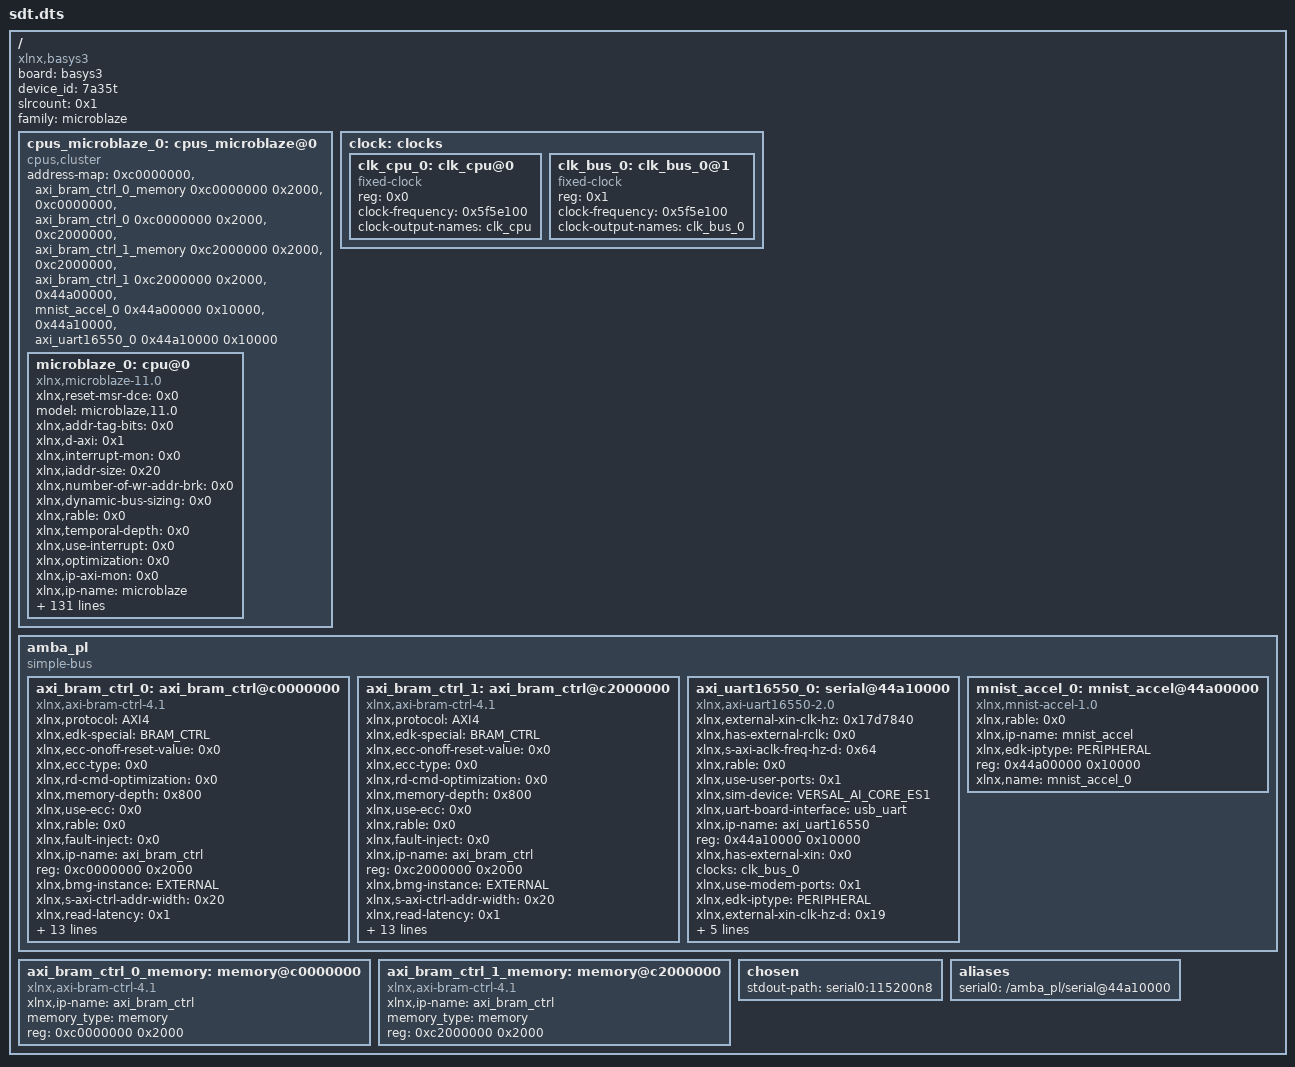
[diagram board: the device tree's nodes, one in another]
/dts-v1/;

/ {
        board = "basys3";
        compatible = "xlnx,basys3";
        device_id = "7a35t";
        #address-cells = <0x1>;
        #size-cells = <0x1>;
        slrcount = <0x1>;
        family = "microblaze";

        cpus_microblaze_0: cpus_microblaze@0 {
                #cpu-mask-cells = <0x1>;
                compatible = "cpus,cluster";
                #address-cells = <0x1>;
                #size-cells = <0x0>;
                address-map = <0xc0000000 &axi_bram_ctrl_0_memory 0xc0000000 0x2000>,
                 <0xc0000000 &axi_bram_ctrl_0 0xc0000000 0x2000>,
                 <0xc2000000 &axi_bram_ctrl_1_memory 0xc2000000 0x2000>,
                 <0xc2000000 &axi_bram_ctrl_1 0xc2000000 0x2000>,
                 <0x44a00000 &mnist_accel_0 0x44a00000 0x10000>,
                 <0x44a10000 &axi_uart16550_0 0x44a10000 0x10000>;
                #ranges-address-cells = <0x1>;
                #ranges-size-cells = <0x1>;
                phandle = <0x9>;

                microblaze_0: cpu@0 {
                        xlnx,reset-msr-dce = <0x0>;
                        model = "microblaze,11.0";
                        xlnx,addr-tag-bits = <0x0>;
                        xlnx,d-axi = <0x1>;
                        xlnx,interrupt-mon = <0x0>;
                        xlnx,iaddr-size = <0x20>;
                        xlnx,number-of-wr-addr-brk = <0x0>;
                        xlnx,dynamic-bus-sizing = <0x0>;
                        xlnx,rable = <0x0>;
                        xlnx,temporal-depth = <0x0>;
                        xlnx,use-interrupt = <0x0>;
                        xlnx,optimization = <0x0>;
                        xlnx,ip-axi-mon = <0x0>;
                        xlnx,ip-name = "microblaze";
                        d-cache-highaddr = <0x3fffffff>;
                        xlnx,dcache-force-tag-lutram = <0x0>;
                        xlnx,pc-width = <0x20>;
                        xlnx,interrupt-is-edge = <0x0>;
                        reg = <0x0>;
                        xlnx,async-interrupt = <0x1>;
                        xlnx,use-mmu = <0x0>;
                        xlnx,reset-msr-ee = <0x0>;
                        xlnx,icache-victims = <0x0>;
                        xlnx,use-reorder-instr = <0x1>;
                        xlnx,d-lmb-mon = <0x0>;
                        xlnx,d-lmb-protocol = <0x0>;
                        xlnx,ill-opcode-exception = <0x0>;
                        xlnx,dcache-always-used = <0x1>;
                        xlnx,use-div = <0x0>;
                        xlnx,dc-axi-mon = <0x0>;
                        xlnx,debug-trace-async-reset = <0x0>;
                        xlnx,trace = <0x0>;
                        xlnx,part = "xc7a35tcpg236-1";
                        i-cache-baseaddr = <0x0>;
                        xlnx,use-config-reset = <0x0>;
                        xlnx,pvr = <0x0>;
                        xlnx,i-lmb-mon = <0x0>;
                        xlnx,dcache-byte-size = <0x2000>;
                        xlnx,fault-tolerant = <0x1>;
                        xlnx,family = "artix7";
                        compatible = "xlnx,microblaze-11.0", "xlnx,microblaze";
                        xlnx,data-size = <0x20>;
                        xlnx,mmu-zones = <0x10>;
                        xlnx,debug-trace-size = <0x2000>;
                        xlnx,mmu-privileged-instr = <0x0>;
                        xlnx,enable-discrete-ports = <0x0>;
                        d-cache-line-size = <0x10>;
                        xlnx,d-lmb = <0x0>;
                        xlnx,sco = <0x0>;
                        xlnx,reset-msr-eip = <0x0>;
                        xlnx,debug-interface = <0x0>;
                        clock-frequency = <0x5f5e100>;
                        xlnx,use-ext-brk = <0x0>;
                        xlnx,daddr-size = <0x20>;
                        xlnx,debug-enabled = <0x1>;
                        xlnx,reset-msr-ice = <0x0>;
                        xlnx,num-sync-ff-dbg-trace-clk = <0x2>;
                        xlnx,i-lmb-protocol = <0x0>;
                        xlnx,endianness = <0x1>;
                        xlnx,fsl-exception = <0x0>;
                        i-cache-line-size = <0x10>;
                        xlnx,use-extended-fsl-instr = <0x0>;
                        xlnx,reset-msr = <0x0>;
                        xlnx,dp-axi-mon = <0x0>;
                        device_type = "cpu";
                        xlnx,branch-target-cache-size = <0x0>;
                        xlnx,dcache-use-writeback = <0x0>;
                        xlnx,div-zero-exception = <0x0>;
                        xlnx,mmu-tlb-access = <0x3>;
                        bus-handle = <0x7>;
                        xlnx,cache-byte-size = <0x2000>;
                        xlnx,pvr-user2 = <0x0>;
                        xlnx,opcode-0x0-illegal = <0x0>;
                        xlnx,icache-line-len = <0x4>;
                        xlnx,ecc-use-ce-exception = <0x0>;
                        xlnx,base-vectors = <0xc0000000>;
                        xlnx,edk-special = "microblaze";
                        xlnx,use-dcache = <0x0>;
                        xlnx,use-barrel = <0x0>;
                        xlnx,reset-msr-bip = <0x0>;
                        xlnx,allow-dcache-wr = <0x1>;
                        xlnx,addr-size = <0x20>;
                        xlnx,debug-external-trace = <0x0>;
                        xlnx,piaddr-size = <0x20>;
                        i-cache-highaddr = <0x3fffffff>;
                        xlnx,num-sync-ff-clk-debug = <0x2>;
                        xlnx,debug-event-counters = <0x5>;
                        xlnx,fpu-exception = <0x0>;
                        xlnx,allow-icache-wr = <0x1>;
                        xlnx,g-use-exceptions = <0x0>;
                        xlnx,i-axi = <0x1>;
                        xlnx,g-template-list = <0x0>;
                        xlnx,icache-streams = <0x0>;
                        xlnx,dcache-line-len = <0x4>;
                        xlnx,num-sync-ff-clk = <0x2>;
                        xlnx,edk-iptype = "PROCESSOR";
                        xlnx,use-stack-protection = <0x0>;
                        xlnx,use-hw-mul = <0x0>;
                        xlnx,num-sync-ff-dbg-clk = <0x1>;
                        xlnx,interconnect = <0x2>;
                        xlnx,debug-latency-counters = <0x1>;
                        i-cache-size = <0x2000>;
                        xlnx,exceptions-in-delay-slots = <0x1>;
                        xlnx,use-fpu = <0x0>;
                        xlnx,reset-msr-ie = <0x0>;
                        xlnx,edge-is-positive = <0x1>;
                        xlnx,use-pcmp-instr = <0x0>;
                        xlnx,use-icache = <0x0>;
                        d-cache-size = <0x2000>;
                        xlnx,memory-ip-list = "axi_bram_ctrl_0_memory", "axi_bram_ctrl_0_memory", "axi_bram_ctrl_1_memory", "axi_bram_ctrl_1_memory";
                        xlnx,async-wakeup = <0x3>;
                        xlnx,use-non-secure = <0x0>;
                        xlnx,dcache-addr-tag = <0x0>;
                        xlnx,number-of-rd-addr-brk = <0x0>;
                        d-cache-baseaddr = <0x0>;
                        xlnx,area-optimized = <0x0>;
                        xlnx,avoid-primitives = <0x0>;
                        xlnx,lockstep-slave = <0x0>;
                        xlnx,use-ext-nm-brk = <0x0>;
                        xlnx,instr-size = <0x20>;
                        xlnx,icache-always-used = <0x1>;
                        xlnx,i-lmb = <0x0>;
                        xlnx,mmu-dtlb-size = <0x4>;
                        xlnx,lockstep-select = <0x0>;
                        xlnx,lmb-data-size = <0x20>;
                        xlnx,ic-axi-mon = <0x0>;
                        xlnx,enable-conversion = <0x0>;
                        xlnx,num-sync-ff-clk-irq = <0x1>;
                        xlnx,fsl-links = <0x0>;
                        timebase-frequency = <0x5f5e100>;
                        xlnx,icache-force-tag-lutram = <0x0>;
                        xlnx,dcache-data-width = <0x0>;
                        xlnx,dcache-victims = <0x0>;
                        xlnx,use-branch-target-cache = <0x0>;
                        xlnx,debug-profile-size = <0x0>;
                        xlnx,unaligned-exceptions = <0x0>;
                        xlnx,lockstep-master = <0x0>;
                        xlnx,freq = <0x5f5e100>;
                        xlnx,number-of-pc-brk = <0x1>;
                        xlnx,mmu-itlb-size = <0x2>;
                        xlnx,imprecise-exceptions = <0x0>;
                        xlnx,use-msr-instr = <0x0>;
                        xlnx,icache-data-width = <0x0>;
                        xlnx,debug-counter-width = <0x20>;
                        phandle = <0xa>;
                };
        };

        clock: clocks {
                #address-cells = <0x1>;
                #size-cells = <0x0>;
                phandle = <0xb>;

                clk_cpu_0: clk_cpu@0 {
                        compatible = "fixed-clock";
                        reg = <0x0>;
                        clock-frequency = <0x5f5e100>;
                        clock-output-names = "clk_cpu";
                        #clock-cells = <0x0>;
                        phandle = <0xc>;
                };

                clk_bus_0: clk_bus_0@1 {
                        compatible = "fixed-clock";
                        reg = <0x1>;
                        clock-frequency = <0x5f5e100>;
                        clock-output-names = "clk_bus_0";
                        #clock-cells = <0x0>;
                        phandle = <0x8>;
                };
        };

        amba_pl: amba_pl {
                ranges;
                compatible = "simple-bus";
                #address-cells = <0x1>;
                #size-cells = <0x1>;
                phandle = <0x7>;

                axi_bram_ctrl_0: axi_bram_ctrl@c0000000 {
                        xlnx,protocol = "AXI4";
                        xlnx,edk-special = "BRAM_CTRL";
                        compatible = "xlnx,axi-bram-ctrl-4.1";
                        xlnx,ecc-onoff-reset-value = <0x0>;
                        xlnx,ecc-type = <0x0>;
                        xlnx,rd-cmd-optimization = <0x0>;
                        xlnx,memory-depth = <0x800>;
                        xlnx,use-ecc = <0x0>;
                        xlnx,rable = <0x0>;
                        xlnx,fault-inject = <0x0>;
                        xlnx,ip-name = "axi_bram_ctrl";
                        reg = <0xc0000000 0x2000>;
                        xlnx,bmg-instance = "EXTERNAL";
                        xlnx,s-axi-ctrl-addr-width = <0x20>;
                        xlnx,read-latency = <0x1>;
                        xlnx,id-width = <0x0>;
                        xlnx,s-axi-supports-narrow-burst = <0x0>;
                        xlnx,supports-narrow-burst = <0x0>;
                        xlnx,single-port-bram = <0x1>;
                        xlnx,ecc = <0x0>;
                        xlnx,edk-iptype = "PERIPHERAL";
                        status = "okay";
                        xlnx,data-width = <0x20>;
                        xlnx,bram-addr-width = <0xb>;
                        xlnx,bram-inst-mode = "EXTERNAL";
                        xlnx,s-axi-ctrl-data-width = <0x20>;
                        xlnx,mem-depth = <0x800>;
                        xlnx,s-axi-id-width = <0x1>;
                        xlnx,name = "axi_bram_ctrl_0";
                        phandle = <0x2>;
                };

                axi_bram_ctrl_1: axi_bram_ctrl@c2000000 {
                        xlnx,protocol = "AXI4";
                        xlnx,edk-special = "BRAM_CTRL";
                        compatible = "xlnx,axi-bram-ctrl-4.1";
                        xlnx,ecc-onoff-reset-value = <0x0>;
                        xlnx,ecc-type = <0x0>;
                        xlnx,rd-cmd-optimization = <0x0>;
                        xlnx,memory-depth = <0x800>;
                        xlnx,use-ecc = <0x0>;
                        xlnx,rable = <0x0>;
                        xlnx,fault-inject = <0x0>;
                        xlnx,ip-name = "axi_bram_ctrl";
                        reg = <0xc2000000 0x2000>;
                        xlnx,bmg-instance = "EXTERNAL";
                        xlnx,s-axi-ctrl-addr-width = <0x20>;
                        xlnx,read-latency = <0x1>;
                        xlnx,id-width = <0x0>;
                        xlnx,s-axi-supports-narrow-burst = <0x0>;
                        xlnx,supports-narrow-burst = <0x0>;
                        xlnx,single-port-bram = <0x1>;
                        xlnx,ecc = <0x0>;
                        xlnx,edk-iptype = "PERIPHERAL";
                        status = "okay";
                        xlnx,data-width = <0x20>;
                        xlnx,bram-addr-width = <0xb>;
                        xlnx,bram-inst-mode = "EXTERNAL";
                        xlnx,s-axi-ctrl-data-width = <0x20>;
                        xlnx,mem-depth = <0x800>;
                        xlnx,s-axi-id-width = <0x1>;
                        xlnx,name = "axi_bram_ctrl_1";
                        phandle = <0x4>;
                };

                axi_uart16550_0: serial@44a10000 {
                        compatible = "xlnx,axi-uart16550-2.0";
                        xlnx,external-xin-clk-hz = <0x17d7840>;
                        xlnx,has-external-rclk = <0x0>;
                        xlnx,s-axi-aclk-freq-hz-d = <0x64>;
                        xlnx,rable = <0x0>;
                        xlnx,use-user-ports = <0x1>;
                        xlnx,sim-device = "VERSAL_AI_CORE_ES1";
                        xlnx,uart-board-interface = "usb_uart";
                        xlnx,ip-name = "axi_uart16550";
                        reg = <0x44a10000 0x10000>;
                        xlnx,has-external-xin = <0x0>;
                        clocks = <&clk_bus_0>;
                        xlnx,use-modem-ports = <0x1>;
                        xlnx,edk-iptype = "PERIPHERAL";
                        status = "okay";
                        xlnx,external-xin-clk-hz-d = <0x19>;
                        xlnx,clock-freq = <0x5f5e100>;
                        xlnx,use-board-flow;
                        xlnx,base-user = <0x1>;
                        xlnx,is-a-16550 = <0x1>;
                        xlnx,name = "axi_uart16550_0";
                        phandle = <0x6>;
                };

                mnist_accel_0: mnist_accel@44a00000 {
                        xlnx,rable = <0x0>;
                        compatible = "xlnx,mnist-accel-1.0";
                        status = "okay";
                        xlnx,ip-name = "mnist_accel";
                        xlnx,edk-iptype = "PERIPHERAL";
                        reg = <0x44a00000 0x10000>;
                        xlnx,name = "mnist_accel_0";
                        phandle = <0x5>;
                };
        };

        axi_bram_ctrl_0_memory: memory@c0000000 {
                compatible = "xlnx,axi-bram-ctrl-4.1";
                xlnx,ip-name = "axi_bram_ctrl";
                device_type = "memory";
                memory_type = "memory";
                reg = <0xc0000000 0x2000>;
                phandle = <0x1>;
        };

        axi_bram_ctrl_1_memory: memory@c2000000 {
                compatible = "xlnx,axi-bram-ctrl-4.1";
                xlnx,ip-name = "axi_bram_ctrl";
                device_type = "memory";
                memory_type = "memory";
                reg = <0xc2000000 0x2000>;
                phandle = <0x3>;
        };

        chosen {
                stdout-path = "serial0:115200n8";
        };

        aliases {
                serial0 = "/amba_pl/serial@44a10000";
        };

        __symbols__ {
                cpus_microblaze_0 = "/cpus_microblaze@0";
                microblaze_0 = "/cpus_microblaze@0/cpu@0";
                clock = "/clocks";
                clk_cpu_0 = "/clocks/clk_cpu@0";
                clk_bus_0 = "/clocks/clk_bus_0@1";
                amba_pl = "/amba_pl";
                axi_bram_ctrl_0 = "/amba_pl/axi_bram_ctrl@c0000000";
                axi_bram_ctrl_1 = "/amba_pl/axi_bram_ctrl@c2000000";
                axi_uart16550_0 = "/amba_pl/serial@44a10000";
                mnist_accel_0 = "/amba_pl/mnist_accel@44a00000";
                axi_bram_ctrl_0_memory = "/memory@c0000000";
                axi_bram_ctrl_1_memory = "/memory@c2000000";
        };
};
